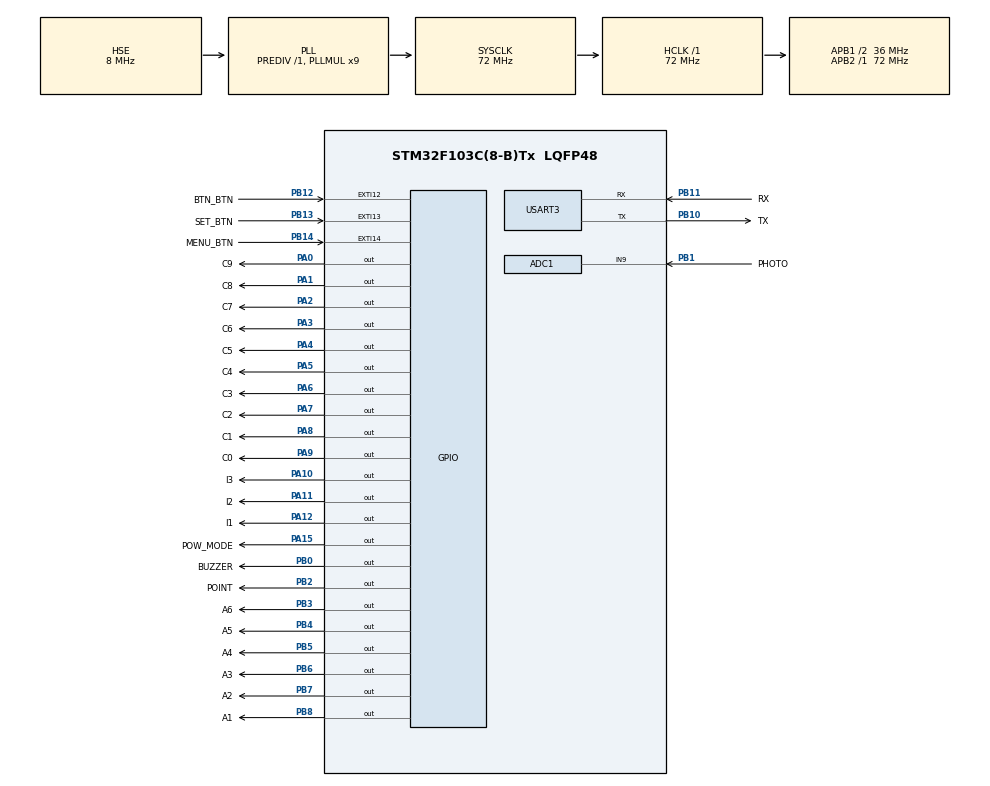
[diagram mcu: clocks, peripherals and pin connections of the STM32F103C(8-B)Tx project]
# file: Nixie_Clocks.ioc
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ADC1.Channel-0\#ChannelRegularConversion=ADC_CHANNEL_9
ADC1.NbrOfConversionFlag=1
ADC1.Rank-0\#ChannelRegularConversion=1
ADC1.SamplingTime-0\#ChannelRegularConversion=ADC_SAMPLETIME_1CYCLE_5
ADC1.master=1
Mcu.Family=STM32F1
Mcu.Name=STM32F103C(8-B)Tx
Mcu.Package=LQFP48
NVIC.EXTI15_10_IRQn=true\:0\:0\:false\:false\:true
NVIC.PriorityGroup=NVIC_PRIORITYGROUP_4
NVIC.RTC_IRQn=true\:0\:0\:false\:false\:true
NVIC.TIM1_CC_IRQn=true\:0\:0\:false\:false\:true
NVIC.TIM1_UP_IRQn=true\:0\:0\:false\:false\:true
PA0-WKUP.GPIO_Label=C9
PA0-WKUP.GPIO_Speed=GPIO_SPEED_FREQ_HIGH
PA0-WKUP.Signal=GPIO_Output
PA1.GPIO_Label=C8
PA1.GPIO_Speed=GPIO_SPEED_FREQ_HIGH
PA1.Signal=GPIO_Output
PA10.GPIO_Label=I3
PA10.GPIO_Speed=GPIO_SPEED_FREQ_LOW
PA10.Signal=GPIO_Output
PA11.GPIO_Label=I2
PA11.Signal=GPIO_Output
PA12.GPIO_Label=I1
PA12.Signal=GPIO_Output
PA13.Mode=Serial_Wire
PA13.Signal=SYS_JTMS-SWDIO
PA14.Mode=Serial_Wire
PA14.Signal=SYS_JTCK-SWCLK
PA15.GPIO_Label=POW_MODE
PA15.Signal=GPIO_Output
PA2.GPIO_Label=C7
PA2.GPIO_Speed=GPIO_SPEED_FREQ_HIGH
PA2.Signal=GPIO_Output
PA3.GPIO_Label=C6
PA3.GPIO_Speed=GPIO_SPEED_FREQ_HIGH
PA3.Signal=GPIO_Output
PA4.GPIO_Label=C5
PA4.GPIO_Speed=GPIO_SPEED_FREQ_HIGH
PA4.Signal=GPIO_Output
PA5.GPIO_Label=C4
PA5.GPIO_Speed=GPIO_SPEED_FREQ_HIGH
PA5.Signal=GPIO_Output
PA6.GPIO_Label=C3
PA6.GPIO_Speed=GPIO_SPEED_FREQ_HIGH
PA6.Signal=GPIO_Output
PA7.GPIO_Label=C2
PA7.GPIO_Speed=GPIO_SPEED_FREQ_HIGH
PA7.Signal=GPIO_Output
PA8.GPIO_Label=C1
PA8.GPIO_Speed=GPIO_SPEED_FREQ_HIGH
PA8.Signal=GPIO_Output
PA9.GPIO_Label=C0
PA9.GPIO_Speed=GPIO_SPEED_FREQ_HIGH
PA9.Signal=GPIO_Output
PB0.GPIO_Label=BUZZER
PB0.Signal=GPIO_Output
PB1.GPIO_Label=PHOTO
PB1.Signal=ADCx_IN9
PB10.GPIO_Label=TX
PB10.Mode=Asynchronous
PB10.Signal=USART3_TX
PB11.GPIO_Label=RX
PB11.Mode=Asynchronous
PB11.Signal=USART3_RX
PB12.GPIO_Label=BTN_BTN
PB12.GPIO_ModeDefaultEXTI=GPIO_MODE_IT_FALLING
PB12.GPIO_PuPd=GPIO_PULLUP
PB12.Signal=GPXTI12
PB13.GPIO_Label=SET_BTN
PB13.GPIO_ModeDefaultEXTI=GPIO_MODE_IT_FALLING
PB13.GPIO_PuPd=GPIO_PULLUP
PB13.Signal=GPXTI13
PB14.GPIO_Label=MENU_BTN
PB14.GPIO_ModeDefaultEXTI=GPIO_MODE_IT_FALLING
PB14.GPIO_PuPd=GPIO_PULLUP
PB14.Signal=GPXTI14
PB2.GPIO_Label=POINT
PB2.Signal=GPIO_Output
PB3.GPIO_Label=A6
PB3.GPIO_Speed=GPIO_SPEED_FREQ_HIGH
PB3.Signal=GPIO_Output
PB4.GPIO_Label=A5
PB4.GPIO_Speed=GPIO_SPEED_FREQ_HIGH
PB4.Signal=GPIO_Output
PB5.GPIO_Label=A4
PB5.GPIO_Speed=GPIO_SPEED_FREQ_HIGH
PB5.Signal=GPIO_Output
PB6.GPIO_Label=A3
PB6.GPIO_Speed=GPIO_SPEED_FREQ_HIGH
PB6.Signal=GPIO_Output
PB7.GPIO_Label=A2
PB7.GPIO_Speed=GPIO_SPEED_FREQ_HIGH
PB7.Signal=GPIO_Output
PB8.GPIO_Label=A1
PB8.GPIO_Speed=GPIO_SPEED_FREQ_HIGH
PB8.Signal=GPIO_Output
PC14-OSC32_IN.Mode=LSE-External-Oscillator
PC14-OSC32_IN.Signal=RCC_OSC32_IN
PC15-OSC32_OUT.Mode=LSE-External-Oscillator
PC15-OSC32_OUT.Signal=RCC_OSC32_OUT
PD0-OSC_IN.Mode=HSE-External-Oscillator
PD0-OSC_IN.Signal=RCC_OSC_IN
PD1-OSC_OUT.Mode=HSE-External-Oscillator
PD1-OSC_OUT.Signal=RCC_OSC_OUT
ProjectManager.HeapSize=0x200
ProjectManager.StackSize=0x400
ProjectManager.TargetToolchain=EWARM
RCC.ADCPresc=RCC_ADCPCLK2_DIV6
RCC.AHBFreq_Value=72000000
RCC.APB1CLKDivider=RCC_HCLK_DIV2
RCC.APB1Freq_Value=36000000
RCC.APB1TimFreq_Value=72000000
RCC.APB2Freq_Value=72000000
RCC.APB2TimFreq_Value=72000000
RCC.HCLKFreq_Value=72000000
RCC.PLLMUL=RCC_PLL_MUL9
RCC.PLLSourceVirtual=RCC_PLLSOURCE_HSE
RCC.RTCClockSelection=RCC_RTCCLKSOURCE_LSE
RCC.SYSCLKFreq_VALUE=72000000
RCC.SYSCLKSource=RCC_SYSCLKSOURCE_PLLCLK
RCC.USBFreq_Value=72000000
RTC.Format=RTC_FORMAT_BCD
SH.ADCx_IN9.0=ADC1_IN9,IN9
TIM1.Channel-Output\ Compare1\ No\ Output=TIM_CHANNEL_1
TIM1.Period=65000
TIM1.Pulse-Output\ Compare1\ No\ Output=1000
USART3.VirtualMode=VM_ASYNC
VP_RTC_VS_RTC_Activate.Mode=RTC_Enabled
VP_RTC_VS_RTC_Calendar.Mode=RTC_Calendar
VP_TIM1_VS_ClockSourceINT.Mode=Internal
VP_TIM1_VS_no_output1.Mode=Output Compare1 No Output
board=Nixie_Clocks

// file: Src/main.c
/**
  ******************************************************************************
  * File Name          : main.c
  * Description        : Main program body
  ******************************************************************************
  ** This notice applies to any and all portions of this file
  * that are not between comment pairs USER CODE BEGIN and
  * USER CODE END. Other portions of this file, whether
  * inserted by the user or by software development tools
  * are owned by their respective copyright owners.
  *
  * COPYRIGHT(c) 2018 STMicroelectronics
  *
  * Redistribution and use in source and binary forms, with or without modification,
  * are permitted provided that the following conditions are met:
  *   1. Redistributions of source code must retain the above copyright notice,
  *      this list of conditions and the following disclaimer.
  *   2. Redistributions in binary form must reproduce the above copyright notice,
  *      this list of conditions and the following disclaimer in the documentation
  *      and/or other materials provided with the distribution.
  *   3. Neither the name of STMicroelectronics nor the names of its contributors
  *      may be used to endorse or promote products derived from this software
  *      without specific prior written permission.
  *
  * THIS SOFTWARE IS PROVIDED BY THE COPYRIGHT HOLDERS AND CONTRIBUTORS "AS IS"
  * AND ANY EXPRESS OR IMPLIED WARRANTIES, INCLUDING, BUT NOT LIMITED TO, THE
  * IMPLIED WARRANTIES OF MERCHANTABILITY AND FITNESS FOR A PARTICULAR PURPOSE ARE
  * DISCLAIMED. IN NO EVENT SHALL THE COPYRIGHT HOLDER OR CONTRIBUTORS BE LIABLE
  * FOR ANY DIRECT, INDIRECT, INCIDENTAL, SPECIAL, EXEMPLARY, OR CONSEQUENTIAL
  * DAMAGES (INCLUDING, BUT NOT LIMITED TO, PROCUREMENT OF SUBSTITUTE GOODS OR
  * SERVICES; LOSS OF USE, DATA, OR PROFITS; OR BUSINESS INTERRUPTION) HOWEVER
  * CAUSED AND ON ANY THEORY OF LIABILITY, WHETHER IN CONTRACT, STRICT LIABILITY,
  * OR TORT (INCLUDING NEGLIGENCE OR OTHERWISE) ARISING IN ANY WAY OUT OF THE USE
  * OF THIS SOFTWARE, EVEN IF ADVISED OF THE POSSIBILITY OF SUCH DAMAGE.
  *
  ******************************************************************************
  */
#include "main.h"
#include "stm32f1xx_hal.h"
#include "adc.h"
#include "rtc.h"
#include "tim.h"
#include "usart.h"
#include "gpio.h"

/* USER CODE BEGIN PV */
/* Private variables ---------------------------------------------------------*/

/* USER CODE END PV */

void SystemClock_Config(void);

/* USER CODE BEGIN PFP */
/* Private function prototypes -----------------------------------------------*/

/* USER CODE END PFP */

int main(void)
{

  /* MCU Configuration----------------------------------------------------------*/

  /* Reset of all peripherals, Initializes the Flash interface and the Systick. */
  HAL_Init();

  /* Configure the system clock */
  SystemClock_Config();

  /* Initialize all configured peripherals */
  MX_GPIO_Init();
  MX_RTC_Init();
  MX_ADC1_Init();
  MX_USART3_UART_Init();
  MX_TIM1_Init();

  /* USER CODE BEGIN 2 */

  HAL_TIM_Base_Start(&htim1);
  HAL_TIM_PWM_Start(&htim1, TIM_CHANNEL_1);

  /* USER CODE END 2 */

  /* Infinite loop */
  while (1)
  {

  }

}

/** System Clock Configuration
*/
void SystemClock_Config(void)
{

  RCC_OscInitTypeDef RCC_OscInitStruct;
  RCC_ClkInitTypeDef RCC_ClkInitStruct;
  RCC_PeriphCLKInitTypeDef PeriphClkInit;

    /**Initializes the CPU, AHB and APB busses clocks
    */
  RCC_OscInitStruct.OscillatorType = RCC_OSCILLATORTYPE_HSE|RCC_OSCILLATORTYPE_LSE;
  RCC_OscInitStruct.HSEState = RCC_HSE_ON;
  RCC_OscInitStruct.HSEPredivValue = RCC_HSE_PREDIV_DIV1;
  RCC_OscInitStruct.LSEState = RCC_LSE_ON;
  RCC_OscInitStruct.HSIState = RCC_HSI_ON;
  RCC_OscInitStruct.PLL.PLLState = RCC_PLL_ON;
  RCC_OscInitStruct.PLL.PLLSource = RCC_PLLSOURCE_HSE;
  RCC_OscInitStruct.PLL.PLLMUL = RCC_PLL_MUL9;
  if (HAL_RCC_OscConfig(&RCC_OscInitStruct) != HAL_OK)
  {
    _Error_Handler(__FILE__, __LINE__);
  }

    /**Initializes the CPU, AHB and APB busses clocks
    */
  RCC_ClkInitStruct.ClockType = RCC_CLOCKTYPE_HCLK|RCC_CLOCKTYPE_SYSCLK
                              |RCC_CLOCKTYPE_PCLK1|RCC_CLOCKTYPE_PCLK2;
  RCC_ClkInitStruct.SYSCLKSource = RCC_SYSCLKSOURCE_PLLCLK;
  RCC_ClkInitStruct.AHBCLKDivider = RCC_SYSCLK_DIV1;
  RCC_ClkInitStruct.APB1CLKDivider = RCC_HCLK_DIV2;
  RCC_ClkInitStruct.APB2CLKDivider = RCC_HCLK_DIV1;

  if (HAL_RCC_ClockConfig(&RCC_ClkInitStruct, FLASH_LATENCY_2) != HAL_OK)
  {
    _Error_Handler(__FILE__, __LINE__);
  }

  PeriphClkInit.PeriphClockSelection = RCC_PERIPHCLK_RTC|RCC_PERIPHCLK_ADC;
  PeriphClkInit.RTCClockSelection = RCC_RTCCLKSOURCE_LSE;
  PeriphClkInit.AdcClockSelection = RCC_ADCPCLK2_DIV6;
  if (HAL_RCCEx_PeriphCLKConfig(&PeriphClkInit) != HAL_OK)
  {
    _Error_Handler(__FILE__, __LINE__);
  }

    /**Configure the Systick interrupt time
    */
  HAL_SYSTICK_Config(HAL_RCC_GetHCLKFreq()/1000);

    /**Configure the Systick
    */
  HAL_SYSTICK_CLKSourceConfig(SYSTICK_CLKSOURCE_HCLK);

  /* SysTick_IRQn interrupt configuration */
  HAL_NVIC_SetPriority(SysTick_IRQn, 0, 0);
}

void _Error_Handler(char * file, int line)
{
  while(1)
  {
  }
}

/************************ (C) COPYRIGHT STMicroelectronics *****END OF FILE****/
